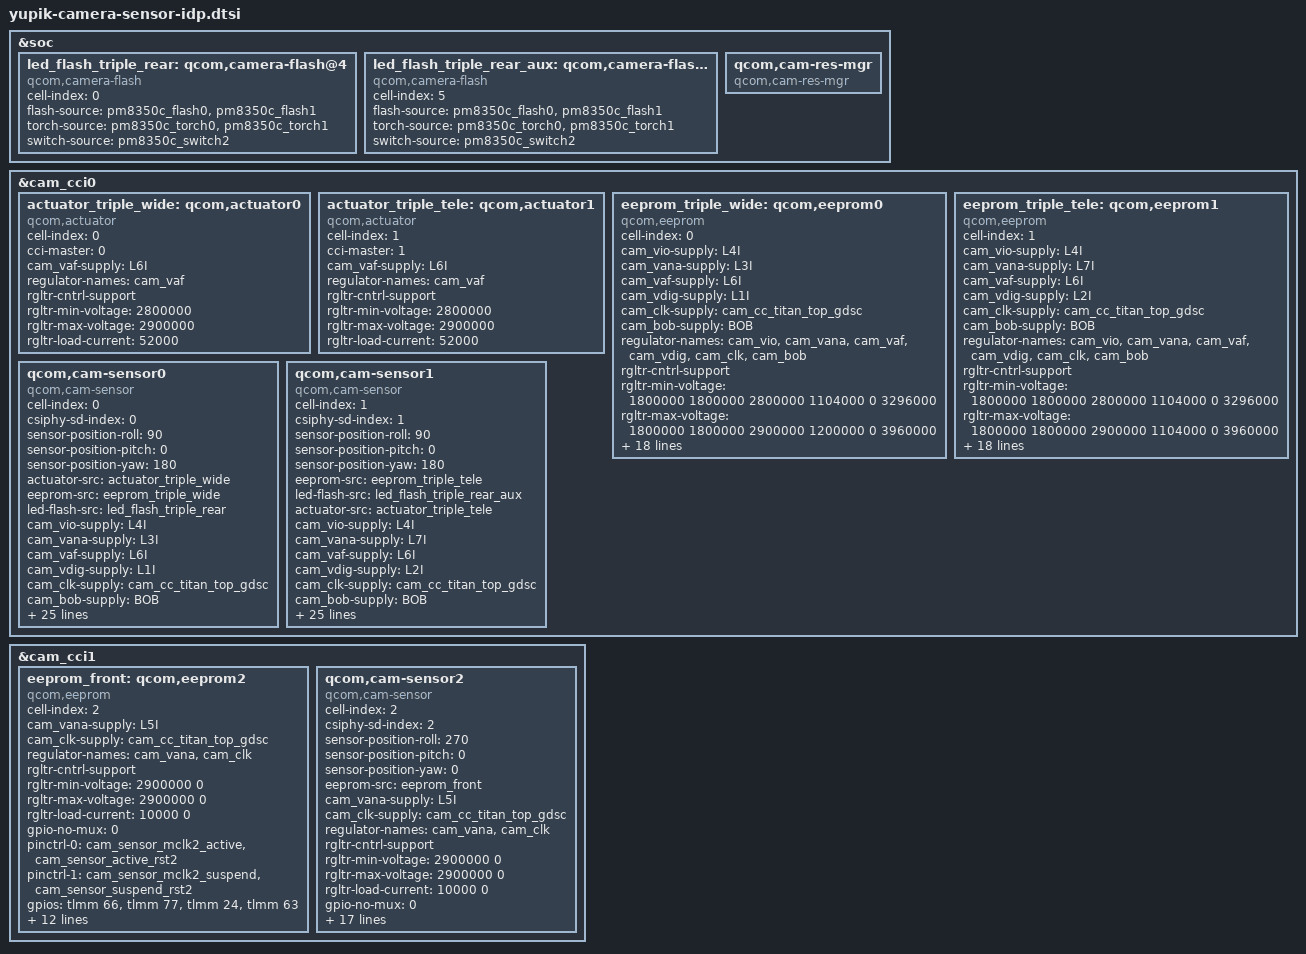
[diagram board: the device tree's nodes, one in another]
#include <dt-bindings/clock/qcom,camcc-yupik.h>

&soc {
	led_flash_triple_rear: qcom,camera-flash@4 {
		cell-index = <0>;
		compatible = "qcom,camera-flash";
		flash-source = <&pm8350c_flash0 &pm8350c_flash1>;
		torch-source = <&pm8350c_torch0 &pm8350c_torch1>;
		switch-source = <&pm8350c_switch2>;
		status = "ok";
	};

	led_flash_triple_rear_aux: qcom,camera-flash@5 {
		cell-index = <5>;
		compatible = "qcom,camera-flash";
		flash-source = <&pm8350c_flash0 &pm8350c_flash1>;
		torch-source = <&pm8350c_torch0 &pm8350c_torch1>;
		switch-source = <&pm8350c_switch2>;
		status = "ok";
	};

	qcom,cam-res-mgr {
		compatible = "qcom,cam-res-mgr";
		status = "ok";
	};
};

&cam_cci0 {
	actuator_triple_wide: qcom,actuator0 {
		cell-index = <0>;
		compatible = "qcom,actuator";
		cci-master = <0>;
		cam_vaf-supply = <&L6I>;
		regulator-names = "cam_vaf";
		rgltr-cntrl-support;
		rgltr-min-voltage = <2800000>;
		rgltr-max-voltage = <2900000>;
		rgltr-load-current = <52000>;
	};

	actuator_triple_tele: qcom,actuator1 {
		cell-index = <1>;
		compatible = "qcom,actuator";
		cci-master = <1>;
		cam_vaf-supply = <&L6I>;
		regulator-names = "cam_vaf";
		rgltr-cntrl-support;
		rgltr-min-voltage = <2800000>;
		rgltr-max-voltage = <2900000>;
		rgltr-load-current = <52000>;
	};

	eeprom_triple_wide: qcom,eeprom0 {
		cell-index = <0>;
		compatible = "qcom,eeprom";
		cam_vio-supply = <&L4I>;
		cam_vana-supply = <&L3I>;
		cam_vaf-supply = <&L6I>;
		cam_vdig-supply = <&L1I>;
		cam_clk-supply = <&cam_cc_titan_top_gdsc>;
		cam_bob-supply = <&BOB>;
		regulator-names = "cam_vio", "cam_vana", "cam_vaf", "cam_vdig","cam_clk", "cam_bob";
		rgltr-cntrl-support;
		rgltr-min-voltage = <1800000 1800000 2800000 1104000 0 3296000>;
		rgltr-max-voltage = <1800000 1800000 2900000 1200000 0 3960000>;
		rgltr-load-current = <5000 5000 52000 805000 0 2000000>;
		gpio-no-mux = <0>;
		pinctrl-names = "cam_default", "cam_suspend";
		pinctrl-0 = <&cam_sensor_mclk0_active
				&cam_sensor_active_rst0>;
		pinctrl-1 = <&cam_sensor_mclk0_suspend
				&cam_sensor_suspend_rst0>;
		gpios = <&tlmm 64 0>,
			<&tlmm 20 0>,
			<&tlmm 19 0>;
		gpio-reset = <1>;
		gpio-custom1 = <2>;
		gpio-req-tbl-num = <0 1 2>;
		gpio-req-tbl-flags = <1 0 0>;
		gpio-req-tbl-label = "CAMIF_MCLK0",
					"CAM_RESET0",
					"CAM_VANA";
		cci-master = <0>;
		status = "ok";
		clocks = <&camcc CAM_CC_MCLK0_CLK>;
		clock-names = "cam_clk";
		clock-cntl-level = "nominal";
		clock-rates = <24000000>;
	};

	eeprom_triple_tele: qcom,eeprom1 {
		cell-index = <1>;
		compatible = "qcom,eeprom";
		cam_vio-supply = <&L4I>;
		cam_vana-supply = <&L7I>;
		cam_vaf-supply = <&L6I>;
		cam_vdig-supply = <&L2I>;
		cam_clk-supply = <&cam_cc_titan_top_gdsc>;
		cam_bob-supply = <&BOB>;
		regulator-names = "cam_vio", "cam_vana", "cam_vaf", "cam_vdig",
			"cam_clk", "cam_bob";
		rgltr-cntrl-support;
		rgltr-min-voltage = <1800000 1800000 2800000 1104000 0 3296000>;
		rgltr-max-voltage = <1800000 1800000 2900000 1104000 0 3960000>;
		rgltr-load-current = <10000 10000 52000 140000 0 2000000>;
		gpio-no-mux = <0>;
		pinctrl-names = "cam_default", "cam_suspend";
		pinctrl-0 = <&cam_sensor_mclk1_active
				&cam_sensor_active_rst1>;
		pinctrl-1 = <&cam_sensor_mclk1_suspend
				&cam_sensor_suspend_rst1>;
		gpios = <&tlmm 65 0>,
			<&tlmm 21 0>,
			<&tlmm 15 0>;
		gpio-reset = <1>;
		gpio-custom1 = <2>;
		gpio-req-tbl-num = <0 1 2>;
		gpio-req-tbl-flags = <1 0 0>;
		gpio-req-tbl-label = "CAMIF_MCLK1",
					"CAM_RESET1",
					"CAM_VANA1";
		cci-master = <1>;
		status = "ok";
		clocks = <&camcc CAM_CC_MCLK1_CLK>;
		clock-names = "cam_clk";
		clock-cntl-level = "nominal";
		clock-rates = <24000000>;
	};

	/* Rear (W) */
	qcom,cam-sensor0 {
		cell-index = <0>;
		compatible = "qcom,cam-sensor";
		csiphy-sd-index = <0>;
		sensor-position-roll = <90>;
		sensor-position-pitch = <0>;
		sensor-position-yaw = <180>;
		actuator-src = <&actuator_triple_wide>;
		eeprom-src = <&eeprom_triple_wide>;
		led-flash-src = <&led_flash_triple_rear>;
		cam_vio-supply = <&L4I>;
		cam_vana-supply = <&L3I>;
		cam_vaf-supply = <&L6I>;
		cam_vdig-supply = <&L1I>;
		cam_clk-supply = <&cam_cc_titan_top_gdsc>;
		cam_bob-supply = <&BOB>;
		regulator-names = "cam_vio", "cam_vana", "cam_vaf", "cam_vdig","cam_clk", "cam_bob";
		rgltr-cntrl-support;
		rgltr-min-voltage = <1800000 1800000 2800000 1104000 0 3296000>;
		rgltr-max-voltage = <1800000 1800000 2900000 1200000 0 3960000>;
		rgltr-load-current = <5000 5000 52000 805000 0 2000000>;
		gpio-no-mux = <0>;
		pinctrl-names = "cam_default", "cam_suspend";
		pinctrl-0 = <&cam_sensor_mclk0_active
				&cam_sensor_active_rst0>;
		pinctrl-1 = <&cam_sensor_mclk0_suspend
				&cam_sensor_suspend_rst0>;
		gpios = <&tlmm 64 0>,
			<&tlmm 20 0>,
			<&tlmm 19 0>;
		gpio-reset = <1>;
		gpio-custom1 = <2>;
		gpio-req-tbl-num = <0 1 2>;
		gpio-req-tbl-flags = <1 0 0>;
		gpio-req-tbl-label = "CAMIF_MCLK0",
					"CAM_RESET0",
					"CAM_VANA";
		cci-master = <0>;
		status = "ok";
		clocks = <&camcc CAM_CC_MCLK0_CLK>;
		clock-names = "cam_clk";
		clock-cntl-level = "nominal";
		clock-rates = <24000000>;
	};

	/* Rear-aux (T) */
	qcom,cam-sensor1 {
		cell-index = <1>;
		compatible = "qcom,cam-sensor";
		csiphy-sd-index = <1>;
		sensor-position-roll = <90>;
		sensor-position-pitch = <0>;
		sensor-position-yaw = <180>;
		eeprom-src = <&eeprom_triple_tele>;
		led-flash-src = <&led_flash_triple_rear_aux>;
		actuator-src = <&actuator_triple_tele>;
		cam_vio-supply = <&L4I>;
		cam_vana-supply = <&L7I>;
		cam_vaf-supply = <&L6I>;
		cam_vdig-supply = <&L2I>;
		cam_clk-supply = <&cam_cc_titan_top_gdsc>;
		cam_bob-supply = <&BOB>;
		regulator-names = "cam_vio", "cam_vana", "cam_vaf", "cam_vdig",
			"cam_clk", "cam_bob";
		rgltr-cntrl-support;
		rgltr-min-voltage = <1800000 1800000 2800000 1104000 0 3296000>;
		rgltr-max-voltage = <1800000 1800000 2900000 1104000 0 3960000>;
		rgltr-load-current = <10000 10000 52000 140000 0 2000000>;
		gpio-no-mux = <0>;
		pinctrl-names = "cam_default", "cam_suspend";
		pinctrl-0 = <&cam_sensor_mclk1_active
				&cam_sensor_active_rst1>;
		pinctrl-1 = <&cam_sensor_mclk1_suspend
				&cam_sensor_suspend_rst1>;
		gpios = <&tlmm 65 0>,
			<&tlmm 21 0>,
			<&tlmm 15 0>;
		gpio-reset = <1>;
		gpio-custom1 = <2>;
		gpio-req-tbl-num = <0 1 2>;
		gpio-req-tbl-flags = <1 0 0>;
		gpio-req-tbl-label = "CAMIF_MCLK1",
					"CAM_RESET1",
					"CAM_VANA1";
		cci-master = <1>;
		status = "ok";
		clocks = <&camcc CAM_CC_MCLK1_CLK>;
		clock-names = "cam_clk";
		clock-cntl-level = "nominal";
		clock-rates = <24000000>;
	};

};

&cam_cci1 {
	eeprom_front: qcom,eeprom2 {
		cell-index = <2>;
		compatible = "qcom,eeprom";
		cam_vana-supply = <&L5I>;
		cam_clk-supply = <&cam_cc_titan_top_gdsc>;
		regulator-names = "cam_vana", "cam_clk";
		rgltr-cntrl-support;
		rgltr-min-voltage = <2900000 0>;
		rgltr-max-voltage = <2900000 0>;
		rgltr-load-current = <10000 0>;
		gpio-no-mux = <0>;
		pinctrl-names = "cam_default", "cam_suspend";
		pinctrl-0 = <&cam_sensor_mclk2_active
				&cam_sensor_active_rst2>;
		pinctrl-1 = <&cam_sensor_mclk2_suspend
				&cam_sensor_suspend_rst2>;
		gpios = <&tlmm 66 0>,
			<&tlmm 77 0>,
			<&tlmm 24 0>,//dvdd
			<&tlmm 63 0>;//vio
		gpio-reset = <1>;
		gpio-custom1 = <2>;
		gpio-custom2 = <3>;
		gpio-req-tbl-num = <0 1 2 3 >;
		gpio-req-tbl-flags = <1 0 0 0>;
		gpio-req-tbl-label = "CAMIF_MCLK2",
					"CAM_RESET2",
					"CAM_VDIG",
					"CAM_VIO";
		sensor-mode = <0>;
		cci-master = <0>;
		status = "ok";
		clocks = <&camcc CAM_CC_MCLK2_CLK>;
		clock-names = "cam_clk";
		clock-cntl-level = "nominal";
		clock-rates = <24000000>;
	};

	/* FRONT */
	qcom,cam-sensor2 {
		cell-index = <2>;
		compatible = "qcom,cam-sensor";
		csiphy-sd-index = <2>;
		sensor-position-roll = <270>;
		sensor-position-pitch = <0>;
		sensor-position-yaw = <0>;
		eeprom-src = <&eeprom_front>;
		cam_vana-supply = <&L5I>;
		cam_clk-supply = <&cam_cc_titan_top_gdsc>;
		regulator-names = "cam_vana", "cam_clk";
		rgltr-cntrl-support;
		rgltr-min-voltage = <2900000 0>;
		rgltr-max-voltage = <2900000 0>;
		rgltr-load-current = <10000 0>;
		gpio-no-mux = <0>;
		pinctrl-names = "cam_default", "cam_suspend";
		pinctrl-0 = <&cam_sensor_mclk2_active
				&cam_sensor_active_rst2>;
		pinctrl-1 = <&cam_sensor_mclk2_suspend
				&cam_sensor_suspend_rst2>;
		gpios = <&tlmm 66 0>,
			<&tlmm 77 0>,
			<&tlmm 24 0>,//dvdd
			<&tlmm 63 0>;//vio
		gpio-reset = <1>;
		gpio-custom1 = <2>;
		gpio-custom2 = <3>;
		gpio-req-tbl-num = <0 1 2 3 >;
		gpio-req-tbl-flags = <1 0 0 0>;
		gpio-req-tbl-label = "CAMIF_MCLK2",
					"CAM_RESET2",
					"CAM_VDIG",
					"CAM_VIO";
		sensor-mode = <0>;
		cci-master = <0>;
		status = "ok";
		clocks = <&camcc CAM_CC_MCLK2_CLK>;
		clock-names = "cam_clk";
		clock-cntl-level = "nominal";
		clock-rates = <24000000>;
	};
};
